# dmpac_targetdb register map
Vendor: Texas Instruments
Registers are 32-bit, read-write, no defined reset value unless marked. A register's access mark holds for its fields unless they carry their own. Offsets are as the file gives them; [hi:lo] are bit positions; {n}, {i} and the like mark numbered series; 'fields as' and 'values as' point back to an identical list.

## DMPAC (part 2 of 5) — Depth and Motion Perception Accelerator (DMPAC)
0x44 exception_pend_clear — The Exception Logging Pending Clear Register allows to clear the pend signal.
  [1:0] pend_clr — Write a 1 to clear the exception pend signal.
0x44 exception_pend_clear — The Exception Logging Pending Clear Register allows to clear the pend signal.
  [1:0] pend_clr — Write a 1 to clear the exception pend signal.
{0x44+0x400*i} msram{i}_fw_region_2_permission_0 (i=0..3) — The FW Region 2 Permission 0 Register defines the permissions for the slave ksbus_msram{i}.slv region 2 firewall.
  [16:8] priv_id — Allowed privid.
  [1] sec_supv_read — Secure supervisor read allowed.
  [2:1] sec_supv_cacheable — Secure supervisor cacheable allowed.
  [3:1] sec_supv_debug — Secure supervisor debug allowed.
  [4:1] sec_user_write — Secure user write allowed.
  [5:1] sec_user_read — Secure user read allowed.
  [6:1] sec_user_cacheable — Secure user cacheable allowed.
  [7:1] sec_user_debug — Secure user debug allowed.
  [8:1] nonsec_supv_write — Non-secure supervisor write allowed.
  [9:1] nonsec_supv_read — Non-secure supervisor read allowed.
  [10:1] nonsec_supv_cacheable — Non-secure supervisor cacheable allowed.
  [11:1] nonsec_supv_debug — Non-secure supervisor debug allowed.
  [12:1] nonsec_user_write — Non-secure user write allowed.
  [13:1] nonsec_user_read — Non-secure user read allowed.
  [14:1] nonsec_user_cacheable — Non-secure user cacheable allowed.
  [15:1] nonsec_user_debug — Non-secure user debug allowed.
  [1:0] sec_supv_write — Secure supervisor write allowed.
0x48 SETEVTENBL7 — System event detection enable register 7 (if number of events > 192)
  [1] Event194DetEn — Event(194) Detection Enable
  [n-193:1] Event{n}DetEn (n=195..224) — Event({n}) Detection Enable
  [1:0] Event193DetEn — Event(193) Detection Enable
0x48 bmbufbase access per field — Base address in SL2
  [24:3] depth_cfg rw — Depth of SL2 buffer
  [20:0] addr_cfg rw — SL2 base byte address. Should be aligned to 64 bytes
{0x48+0x400*i} msram{i}_fw_region_2_permission_1 (i=0..3) — The FW Region 2 Permission 1 Register defines the permissions for the slave ksbus_msram{i}.slv region 2 firewall.
  fields as msram0_fw_region_2_permission_0
0x4C SETEVTENBL8 — System event detection enable register 8 (if number of events > 224)
  [1] Event226DetEn — Event(226) Detection Enable
  [n-225:1] Event{n}DetEn (n=227..256) — Event({n}) Detection Enable
  [1:0] Event225DetEn — Event(225) Detection Enable
0x4C fvbufbase access per field — Base address in SL2
  fields as bmbufbase
{0x4C+0x400*i} msram{i}_fw_region_2_permission_2 (i=0..3) — The FW Region 2 Permission 2 Register defines the permissions for the slave ksbus_msram{i}.slv region 2 firewall.
  fields as msram0_fw_region_2_permission_0
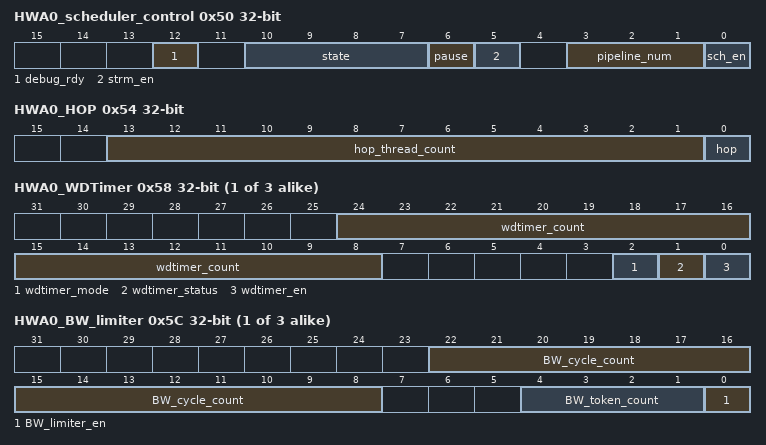
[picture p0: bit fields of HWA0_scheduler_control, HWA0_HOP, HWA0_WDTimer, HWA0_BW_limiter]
0x50 HWA0_scheduler_control access per field — Scheduler Control Register
  [12] debug_rdy rw — '0' -> HWA0 Scheduler resources must not be read during halted state. '1'-> HWA0 Scheduler resources are readable during halted state
  [10:7] state ro — Current state of HWA0 Scheduler
  [6] pause rw — '1' -> pause/suspend scheduler , '0' -> resume scheduler
  [5] strm_en rw — '1' -> Streaming input enable, '0' No streaming input
  [3:1] pipeline_num rw — Pipeline Number of HWA0 Scheduler
  [0] sch_en rw — scheduler enable; write '1' to enable scheduler
0x50 SETMSTID access per field — System Event Master ID
  [8:0] MASTID rw — HW Master ID for System Event module. Software may overwrite the value at any time, but this is only recommended for scenarios where top-level configuration errors result in a collision between HW master IDs
0x50 psa_ctrl access per field — Control register for calculating 32b CRC signature on stereo disparity output
  [1:0] psa_en_cfg rw — Enable calculating 32b CRC signature on 16b stereo disparity and confidence score output
{0x50+0x400*i} msram{i}_fw_region_2_start_address_l access per field (i=0..3) — The FW Region 2 Start Address Low Register defines the start address bits 31 to 0 for the slave ksbus_msram{i}.slv region 2 firewall.
  [20:12] start_address_l rw — Start address bits 31 to 12. Lowest 12 bits are forced to 0 as address must be 4KB aligned.
  [12:0] start_address_lsb ro — Start address bits 11 to 0 are forced to 0 as address must be 4KB aligned.
0x54 HWA0_HOP — Scheduler HOP Control Register. Help in detecting eop within scheduler. Once configured, it counts task/channel starts and stops issuing further start. Specifically useful for Head of pipe dma scheduler .
  [13:1] hop_thread_count — Number of Task count for Head of pipe
  [0] hop — '1' -> Head of Pipe producer Sch , '0' -> No hop
0x54 psa_signature ro — 32b CRC signature calculated on stereo disparity output
  [32:0] crc_sts — 32b CRC signature value as calculated on 16b stereo disparity and confidence score output
{0x54+0x400*i} msram{i}_fw_region_2_start_address_h (i=0..3) — The FW Region 2 Start Address High Register defines the start address bits 47 to 32 for the slave ksbus_msram{i}.slv region 2 firewall.
  [16:0] start_address_h — Start address bits 47 to 32.
{0x58+0xB4*i} HWA{i}_WDTimer access per field (i=0..2) — Watchdog timer control register
  [24:8] wdtimer_count ro — Current value of HWA{i} Scheduler watchdog timer count
  [2] wdtimer_mode rw — Watchdog timeout count '1' -> 128K , '0' -> 64K
  [1] wdtimer_status ro — HWA{i} Scheduler watchdog timer status '1' -> Timer Active '0' -> Timer Inactive (count is stable)
  [0] wdtimer_en rw — '1' -> activate watchdog timer for 64K VPAC/DMPAC cycles between task start and task done '0' -> Disable watchdog timer
{0x58+0x400*i} msram{i}_fw_region_2_end_address_l access per field (i=0..3) — The FW Region 2 End Address Low Register defines the end address bits 31 to 0 to include for the slave ksbus_msram{i}.slv region 2 firewall.
  [20:12] end_address_l rw — End address bits 31 to 12 to include in the match. Lowest 12 bits are forced to 1s as address must be 4KB aligned.
  [12:0] end_address_lsb ro — End address bits 11 to 0 are forced to 1s as address must be 4KB aligned minus 1.
{0x5C+0xB4*i} HWA{i}_BW_limiter (i=0..2) — Scheduler BW Control Register. Processing unit level BW control. Use DMA to eliminate peak system BW within processing units line/Block
  [22:8] BW_cycle_count — Average Cycle count between successive Task Start
  [4:1] BW_token_count — Max Token count to create average BW
  [0] BW_limiter_en — '1' -> Enable BW limiter function for HWA{i} sch, '0' --> Disable
{0x5C+0x400*i} msram{i}_fw_region_2_end_address_h (i=0..3) — The FW Region 2 End Address High Register defines the end address bits 47 to 32 to include for the slave ksbus_msram{i}.slv region 2 firewall.
  [16:0] end_address_h — End address bits 47 to 32 to include in the match.
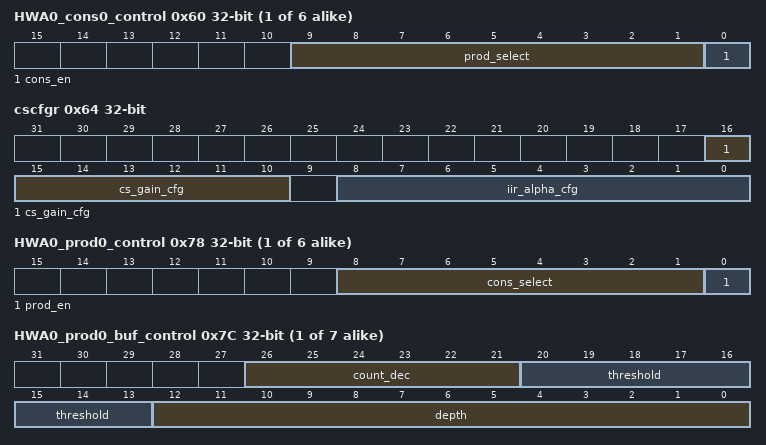
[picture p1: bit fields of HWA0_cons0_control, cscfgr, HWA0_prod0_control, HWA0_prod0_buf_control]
{0x60+4i} HWA0_cons{i}_control (i=0..5) — Controlling consumer socket {i} for HWA0
  [9:1] prod_select — producer select for HWA0 cons socket {i}
  [0] cons_en — '1' -> Consumer socket {i} enable , '0' Disable
0x60 msfr access per field — 5b unsigned integer for Step Search cost function
  [5:0] msf_cfg rw — Motion smoothness factor
0x60 HIST ro — SDE Histogram registers stores the counter value of how many confidence scores (scaled to 7-bits) have fallen into each bin
  [21:11] rsvd — Always read as 0. Writes have no effect.
  [21:0] bin_sts — BIN accumulated counter value. Clear to 0 within a 128 cycle window after hts_sde_init is asserted.
{0x60+0x400*i} msram{i}_fw_region_3_control (i=0..3) — The FW Region 3 Control Register defines the control fields for the slave ksbus_msram{i}.slv region 3 firewall.
  [4:1] lock — Lock region. Once set region values cannot be modified.
  [8:1] background — Background enable for region. There can be 1 backgroun region per FW and foreground regions can have overlapping addresses only with the background region.
  [9:1] cache_mode — Cache mode for region. Set to 1 to check cache permissions. Set to 0 to ignore cache permissions.
  [4:0] enable — Enable region. A value of 0xA enables, others disable.
0x64 cscfgr access per field — Feature filter parameters, confidence score scaling factor setup
  [16:10] cs_gain_cfg rw — Multiplier factor (Gain) for the combined confidence score. The sum of individual scores from different decision trees are multiplied by CS Gain before scaling to final 4bit (16 levels) confidence score value.
  [8:0] iir_alpha_cfg rw — Coefficient for IIR filter used for smoothing horizontal flow vector gradient. The usage can be illustrated as:SmoothU(i,j)= [ U(i,j)*alpha + SmoothU(i-1,j)*beta + round ]>>8where beta = 256-alpharound = 128
{0x64+0x400*i} msram{i}_fw_region_3_permission_0 (i=0..3) — The FW Region 3 Permission 0 Register defines the permissions for the slave ksbus_msram{i}.slv region 3 firewall.
  fields as msram0_fw_region_2_permission_0
{0x68+0x400*i} msram{i}_fw_region_3_permission_1 (i=0..3) — The FW Region 3 Permission 1 Register defines the permissions for the slave ksbus_msram{i}.slv region 3 firewall.
  fields as msram0_fw_region_2_permission_0
{0x6C+0x400*i} msram{i}_fw_region_3_permission_2 (i=0..3) — The FW Region 3 Permission 2 Register defines the permissions for the slave ksbus_msram{i}.slv region 3 firewall.
  fields as msram0_fw_region_2_permission_0
0x70 psa_ctrl access per field — Control register for calculating 32b CRC signature on flow vector output
  [1:0] psa_en_cfg rw — Enable calculating 32b CRC signature on 32b flow vector and confidence score output
{0x70+0x400*i} msram{i}_fw_region_3_start_address_l access per field (i=0..3) — The FW Region 3 Start Address Low Register defines the start address bits 31 to 0 for the slave ksbus_msram{i}.slv region 3 firewall.
  fields as msram0_fw_region_2_start_address_l
0x74 psa_signature ro — 32b CRC signature calculated on flow vector output
  [32:0] crc_sts — 32b CRC signature value as calculated on 32b flow vector and confidence score output
{0x74+0x400*i} msram{i}_fw_region_3_start_address_h (i=0..3) — The FW Region 3 Start Address High Register defines the start address bits 47 to 32 for the slave ksbus_msram{i}.slv region 3 firewall.
  [16:0] start_address_h — Start address bits 47 to 32.
{0x78+0x14*i} HWA0_prod{i}_control (i=0..5) — Controlling producer socket{i} for HWA0
  [8:1] cons_select — consumer select for HWA0 prod socket {i}. Used in decrementing count of producer buffer
  [0] prod_en — '1' -> Producer socket 0 enable , '0' Disable
{0x78+0x400*i} msram{i}_fw_region_3_end_address_l access per field (i=0..3) — The FW Region 3 End Address Low Register defines the end address bits 31 to 0 to include for the slave ksbus_msram{i}.slv region 3 firewall.
  fields as msram0_fw_region_2_end_address_l
{0x7C+0x14*i} HWA0_prod{i}_buf_control (i=0..6) — Controlling producer socket{i} buffer for HWA0
  [26:21] count_dec — Count decrement value for prod count
  [20:13] threshold — Count threshold to generate pend for consumer
  [12:0] depth — Maximum number of producer buffer count
{0x7C+0x400*i} msram{i}_fw_region_3_end_address_h (i=0..3) — The FW Region 3 End Address High Register defines the end address bits 47 to 32 to include for the slave ksbus_msram{i}.slv region 3 firewall.
  fields as msram0_fw_region_2_end_address_h
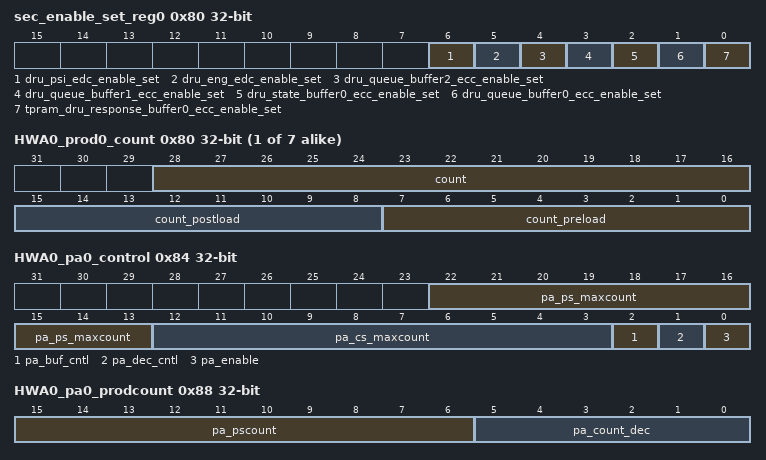
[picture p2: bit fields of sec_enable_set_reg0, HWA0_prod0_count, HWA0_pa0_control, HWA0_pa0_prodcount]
0x80 sec_enable_set_reg0 — Interrupt Enable Set Register 0
  [6] dru_psi_edc_enable_set — Interrupt Enable Set Register for dru_psi_edc_pend
  [5] dru_eng_edc_enable_set — Interrupt Enable Set Register for dru_eng_edc_pend
  [4] dru_queue_buffer2_ecc_enable_set — Interrupt Enable Set Register for dru_queue_buffer2_ecc_pend
  [3] dru_queue_buffer1_ecc_enable_set — Interrupt Enable Set Register for dru_queue_buffer1_ecc_pend
  [2] dru_state_buffer0_ecc_enable_set — Interrupt Enable Set Register for dru_state_buffer0_ecc_pend
  [1] dru_queue_buffer0_ecc_enable_set — Interrupt Enable Set Register for dru_queue_buffer0_ecc_pend
  [0] tpram_dru_response_buffer0_ecc_enable_set — Interrupt Enable Set Register for tpram_dru_response_buffer0_ecc_pend
{0x80+0x14*i} HWA0_prod{i}_count access per field (i=0..6) — Defining count values for pre/post load for generating pend by HWA0 prod{i}
  [28:16] count ro — current count value
  [15:8] count_postload rw — count postload after producer max thread count reached
  [7:0] count_preload rw — count preload after scheduler start/init
0x80 dru_err_evt_set0 wo — DRU Error Event Set Register
  [1] err_evt1 — Set the Error Event for channel 1
  [n:1] err_evt{n} (n=2..31) — Set the Error Event for channel {n}
  [1:0] err_evt0 — Set the Error Event for channel 0
0x84 HWA0_pa0_control — control register to manage pattern adapter on HWA0 prod socket0
  [22:13] pa_ps_maxcount — destination count for pattern adaptation (N), M --> N
  [12:3] pa_cs_maxcount — source count for pattern adaptation (M), M --> N
  [2] pa_buf_cntl — '1' -> Apply threshold, count_preload and count_postload on pattern adapter count (use this only when pa_enable='1') '0' -> Apply threshold, count_preload and count_postload on prod count (same behavior as if no pattern adapter. Note when pa_enable='1' and pa_buf_cntl='0' threshold is not used and ignored)
  [1] pa_dec_cntl — '1' -> post pattern adaptation, decrement ps count by count_dec , '0' -> post pattern adaptation, decrement ps count by pa_cs_maxcount
  [0] pa_enable — '1' -> pa enable, '0' -> disable
0x88 HWA0_pa0_prodcount access per field — count values for HWA0 prod socket0
  [15:6] pa_pscount ro — current count value of pa prod count
  [5:0] pa_count_dec rw — Decrement count value of pa_prod_count after pattern adapter prod count reaches threshold
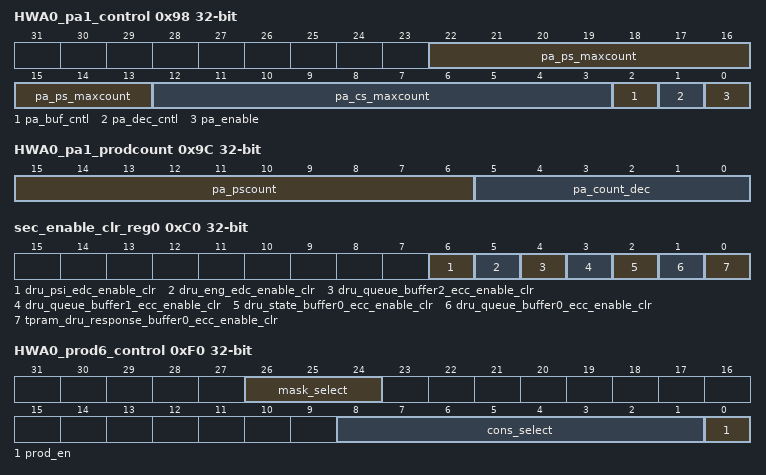
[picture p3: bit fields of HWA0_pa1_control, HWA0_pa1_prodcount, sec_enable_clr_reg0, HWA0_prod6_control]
0x98 HWA0_pa1_control — control register to manage pattern adapter on HWA0 prod socket1
  fields as HWA0_pa0_control
0x9C HWA0_pa1_prodcount access per field — count values for HWA0 prod socket1
  fields as HWA0_pa0_prodcount
0xC0 sec_enable_clr_reg0 — Interrupt Enable Clear Register 0
  [6] dru_psi_edc_enable_clr — Interrupt Enable Clear Register for dru_psi_edc_pend
  [5] dru_eng_edc_enable_clr — Interrupt Enable Clear Register for dru_eng_edc_pend
  [4] dru_queue_buffer2_ecc_enable_clr — Interrupt Enable Clear Register for dru_queue_buffer2_ecc_pend
  [3] dru_queue_buffer1_ecc_enable_clr — Interrupt Enable Clear Register for dru_queue_buffer1_ecc_pend
  [2] dru_state_buffer0_ecc_enable_clr — Interrupt Enable Clear Register for dru_state_buffer0_ecc_pend
  [1] dru_queue_buffer0_ecc_enable_clr — Interrupt Enable Clear Register for dru_queue_buffer0_ecc_pend
  [0] tpram_dru_response_buffer0_ecc_enable_clr — Interrupt Enable Clear Register for tpram_dru_response_buffer0_ecc_pend
0xC0 dru_local_evt_set0 wo — DRU Local Event Set Register
  [1] comp_evt1 — Set the Local Event for channel 1
  [n:1] comp_evt{n} (n=2..31) — Set the Local Event for channel {n}
  [1:0] comp_evt0 — Set the Local Event for channel 0
0xF0 HWA0_prod6_control — Controlling producer socket6 for HWA0
  [26:24] mask_select — define which tdone_mask apply to prod socket 6. tdone_mask[mask_select] applies to prod_socket6
  [8:1] cons_select — consumer select for HWA0 prod socket 6. Used in decrementing count of producer buffer
  [0] prod_en — '1' -> Producer socket 0 enable , '0' Disable
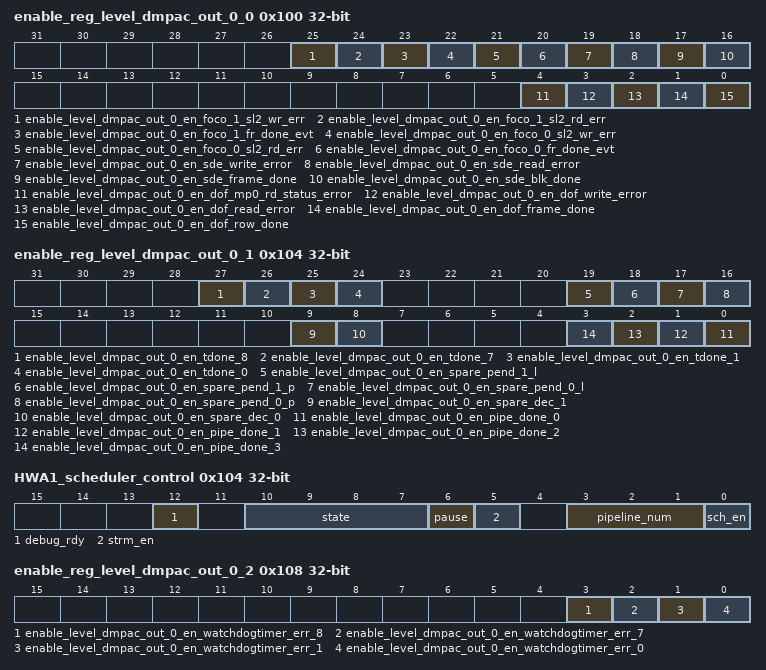
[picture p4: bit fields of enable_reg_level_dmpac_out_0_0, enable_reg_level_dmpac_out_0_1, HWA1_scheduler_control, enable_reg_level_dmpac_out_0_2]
0x100 enable_reg_level_dmpac_out_0_0 — Enable Register 0
  [25] enable_level_dmpac_out_0_en_foco_1_sl2_wr_err — Enable Set for level_dmpac_out_0_en_foco_1_sl2_wr_err
  [24] enable_level_dmpac_out_0_en_foco_1_sl2_rd_err — Enable Set for level_dmpac_out_0_en_foco_1_sl2_rd_err
  [23] enable_level_dmpac_out_0_en_foco_1_fr_done_evt — Enable Set for level_dmpac_out_0_en_foco_1_fr_done_evt
  [22] enable_level_dmpac_out_0_en_foco_0_sl2_wr_err — Enable Set for level_dmpac_out_0_en_foco_0_sl2_wr_err
  [21] enable_level_dmpac_out_0_en_foco_0_sl2_rd_err — Enable Set for level_dmpac_out_0_en_foco_0_sl2_rd_err
  [20] enable_level_dmpac_out_0_en_foco_0_fr_done_evt — Enable Set for level_dmpac_out_0_en_foco_0_fr_done_evt
  [19] enable_level_dmpac_out_0_en_sde_write_error — Enable Set for level_dmpac_out_0_en_sde_write_error
  [18] enable_level_dmpac_out_0_en_sde_read_error — Enable Set for level_dmpac_out_0_en_sde_read_error
  [17] enable_level_dmpac_out_0_en_sde_frame_done — Enable Set for level_dmpac_out_0_en_sde_frame_done
  [16] enable_level_dmpac_out_0_en_sde_blk_done — Enable Set for level_dmpac_out_0_en_sde_blk_done
  [4] enable_level_dmpac_out_0_en_dof_mp0_rd_status_error — Enable Set for level_dmpac_out_0_en_dof_mp0_rd_status_error
  [3] enable_level_dmpac_out_0_en_dof_write_error — Enable Set for level_dmpac_out_0_en_dof_write_error
  [2] enable_level_dmpac_out_0_en_dof_read_error — Enable Set for level_dmpac_out_0_en_dof_read_error
  [1] enable_level_dmpac_out_0_en_dof_frame_done — Enable Set for level_dmpac_out_0_en_dof_frame_done
  [0] enable_level_dmpac_out_0_en_dof_row_done — Enable Set for level_dmpac_out_0_en_dof_row_done
0x104 enable_reg_level_dmpac_out_0_1 — Enable Register 1
  [27] enable_level_dmpac_out_0_en_tdone_8 — Enable Set for level_dmpac_out_0_en_tdone_8
  [26] enable_level_dmpac_out_0_en_tdone_7 — Enable Set for level_dmpac_out_0_en_tdone_7
  [25] enable_level_dmpac_out_0_en_tdone_1 — Enable Set for level_dmpac_out_0_en_tdone_1
  [24] enable_level_dmpac_out_0_en_tdone_0 — Enable Set for level_dmpac_out_0_en_tdone_0
  [19] enable_level_dmpac_out_0_en_spare_pend_1_l — Enable Set for level_dmpac_out_0_en_spare_pend_1_l
  [18] enable_level_dmpac_out_0_en_spare_pend_1_p — Enable Set for level_dmpac_out_0_en_spare_pend_1_p
  [17] enable_level_dmpac_out_0_en_spare_pend_0_l — Enable Set for level_dmpac_out_0_en_spare_pend_0_l
  [16] enable_level_dmpac_out_0_en_spare_pend_0_p — Enable Set for level_dmpac_out_0_en_spare_pend_0_p
  [9] enable_level_dmpac_out_0_en_spare_dec_1 — Enable Set for level_dmpac_out_0_en_spare_dec_1
  [8] enable_level_dmpac_out_0_en_spare_dec_0 — Enable Set for level_dmpac_out_0_en_spare_dec_0
  [n] enable_level_dmpac_out_0_en_pipe_done_{n} (n=0..3) — Enable Set for level_dmpac_out_0_en_pipe_done_{n}
0x104 HWA1_scheduler_control access per field — Scheduler Control Register
  [12] debug_rdy rw — '0' -> HWA1 Scheduler resources must not be read during halted state. '1'-> HWA1 Scheduler resources are readable during halted state
  [10:7] state ro — Current state of HWA1 Scheduler
  [6] pause rw — '1' -> pause/suspend scheduler , '0' -> resume scheduler
  [5] strm_en rw — '1' -> Streaming input enable, '0' No streaming input
  [3:1] pipeline_num rw — Pipeline Number of HWA1 Scheduler
  [0] sch_en rw — scheduler enable; write '1' to enable scheduler
0x108 enable_reg_level_dmpac_out_0_2 — Enable Register 2
  [3] enable_level_dmpac_out_0_en_watchdogtimer_err_8 — Enable Set for level_dmpac_out_0_en_watchdogtimer_err_8
  [2] enable_level_dmpac_out_0_en_watchdogtimer_err_7 — Enable Set for level_dmpac_out_0_en_watchdogtimer_err_7
  [1] enable_level_dmpac_out_0_en_watchdogtimer_err_1 — Enable Set for level_dmpac_out_0_en_watchdogtimer_err_1
  [0] enable_level_dmpac_out_0_en_watchdogtimer_err_0 — Enable Set for level_dmpac_out_0_en_watchdogtimer_err_0
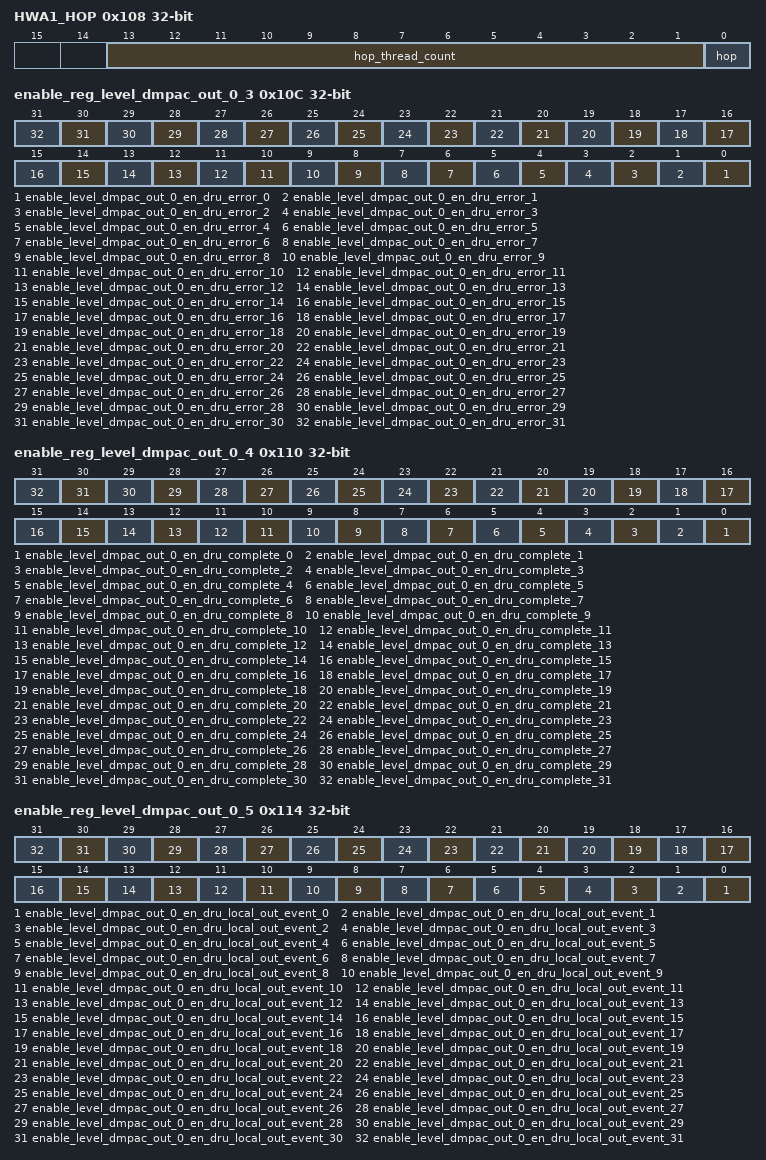
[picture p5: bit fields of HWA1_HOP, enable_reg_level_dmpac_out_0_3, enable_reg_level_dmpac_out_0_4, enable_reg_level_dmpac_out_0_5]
0x108 HWA1_HOP — Scheduler HOP Control Register. Help in detecting eop within scheduler. Once configured, it counts task/channel starts and stops issuing further start. Specifically useful for Head of pipe dma scheduler .
  fields as HWA0_HOP
0x10C enable_reg_level_dmpac_out_0_3 — Enable Register 3
  [n] enable_level_dmpac_out_0_en_dru_error_{n} (n=0..31) — Enable Set for level_dmpac_out_0_en_dru_error_{n}
0x110 enable_reg_level_dmpac_out_0_4 — Enable Register 4
  [n] enable_level_dmpac_out_0_en_dru_complete_{n} (n=0..31) — Enable Set for level_dmpac_out_0_en_dru_complete_{n}
0x114 enable_reg_level_dmpac_out_0_5 — Enable Register 5
  [n] enable_level_dmpac_out_0_en_dru_local_out_event_{n} (n=0..31) — Enable Set for level_dmpac_out_0_en_dru_local_out_event_{n}
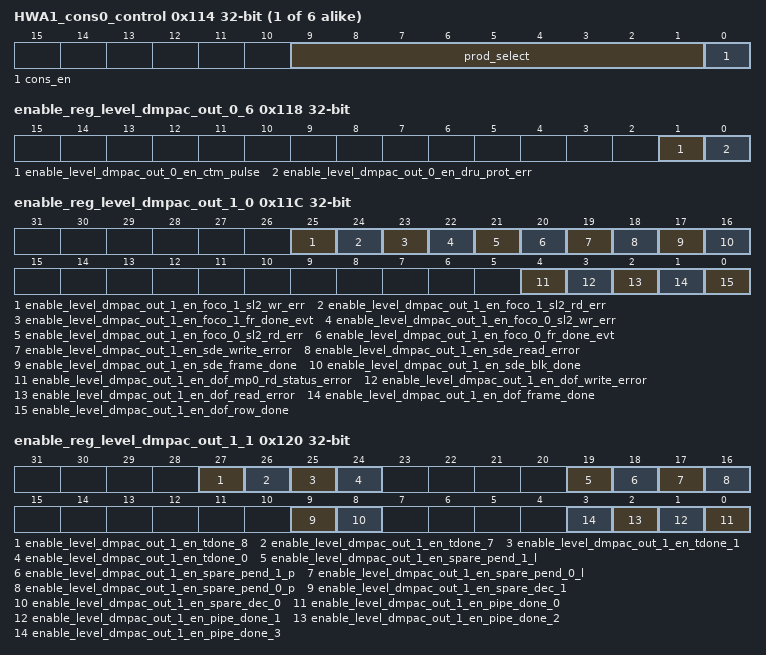
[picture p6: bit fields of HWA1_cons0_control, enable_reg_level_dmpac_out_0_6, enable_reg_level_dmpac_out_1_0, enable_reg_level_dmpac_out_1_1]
{0x114+4i} HWA1_cons{i}_control (i=0..5) — Controlling consumer socket {i} for HWA1
  [9:1] prod_select — producer select for HWA1 cons socket {i}
  [0] cons_en — '1' -> Consumer socket {i} enable , '0' Disable
0x118 enable_reg_level_dmpac_out_0_6 — Enable Register 6
  [1] enable_level_dmpac_out_0_en_ctm_pulse — Enable Set for level_dmpac_out_0_en_ctm_pulse
  [0] enable_level_dmpac_out_0_en_dru_prot_err — Enable Set for level_dmpac_out_0_en_dru_prot_err
0x11C enable_reg_level_dmpac_out_1_0 — Enable Register 7
  [25] enable_level_dmpac_out_1_en_foco_1_sl2_wr_err — Enable Set for level_dmpac_out_1_en_foco_1_sl2_wr_err
  [24] enable_level_dmpac_out_1_en_foco_1_sl2_rd_err — Enable Set for level_dmpac_out_1_en_foco_1_sl2_rd_err
  [23] enable_level_dmpac_out_1_en_foco_1_fr_done_evt — Enable Set for level_dmpac_out_1_en_foco_1_fr_done_evt
  [22] enable_level_dmpac_out_1_en_foco_0_sl2_wr_err — Enable Set for level_dmpac_out_1_en_foco_0_sl2_wr_err
  [21] enable_level_dmpac_out_1_en_foco_0_sl2_rd_err — Enable Set for level_dmpac_out_1_en_foco_0_sl2_rd_err
  [20] enable_level_dmpac_out_1_en_foco_0_fr_done_evt — Enable Set for level_dmpac_out_1_en_foco_0_fr_done_evt
  [19] enable_level_dmpac_out_1_en_sde_write_error — Enable Set for level_dmpac_out_1_en_sde_write_error
  [18] enable_level_dmpac_out_1_en_sde_read_error — Enable Set for level_dmpac_out_1_en_sde_read_error
  [17] enable_level_dmpac_out_1_en_sde_frame_done — Enable Set for level_dmpac_out_1_en_sde_frame_done
  [16] enable_level_dmpac_out_1_en_sde_blk_done — Enable Set for level_dmpac_out_1_en_sde_blk_done
  [4] enable_level_dmpac_out_1_en_dof_mp0_rd_status_error — Enable Set for level_dmpac_out_1_en_dof_mp0_rd_status_error
  [3] enable_level_dmpac_out_1_en_dof_write_error — Enable Set for level_dmpac_out_1_en_dof_write_error
  [2] enable_level_dmpac_out_1_en_dof_read_error — Enable Set for level_dmpac_out_1_en_dof_read_error
  [1] enable_level_dmpac_out_1_en_dof_frame_done — Enable Set for level_dmpac_out_1_en_dof_frame_done
  [0] enable_level_dmpac_out_1_en_dof_row_done — Enable Set for level_dmpac_out_1_en_dof_row_done
0x120 enable_reg_level_dmpac_out_1_1 — Enable Register 8
  [27] enable_level_dmpac_out_1_en_tdone_8 — Enable Set for level_dmpac_out_1_en_tdone_8
  [26] enable_level_dmpac_out_1_en_tdone_7 — Enable Set for level_dmpac_out_1_en_tdone_7
  [25] enable_level_dmpac_out_1_en_tdone_1 — Enable Set for level_dmpac_out_1_en_tdone_1
  [24] enable_level_dmpac_out_1_en_tdone_0 — Enable Set for level_dmpac_out_1_en_tdone_0
  [19] enable_level_dmpac_out_1_en_spare_pend_1_l — Enable Set for level_dmpac_out_1_en_spare_pend_1_l
  [18] enable_level_dmpac_out_1_en_spare_pend_1_p — Enable Set for level_dmpac_out_1_en_spare_pend_1_p
  [17] enable_level_dmpac_out_1_en_spare_pend_0_l — Enable Set for level_dmpac_out_1_en_spare_pend_0_l
  [16] enable_level_dmpac_out_1_en_spare_pend_0_p — Enable Set for level_dmpac_out_1_en_spare_pend_0_p
  [9] enable_level_dmpac_out_1_en_spare_dec_1 — Enable Set for level_dmpac_out_1_en_spare_dec_1
  [8] enable_level_dmpac_out_1_en_spare_dec_0 — Enable Set for level_dmpac_out_1_en_spare_dec_0
  [n] enable_level_dmpac_out_1_en_pipe_done_{n} (n=0..3) — Enable Set for level_dmpac_out_1_en_pipe_done_{n}
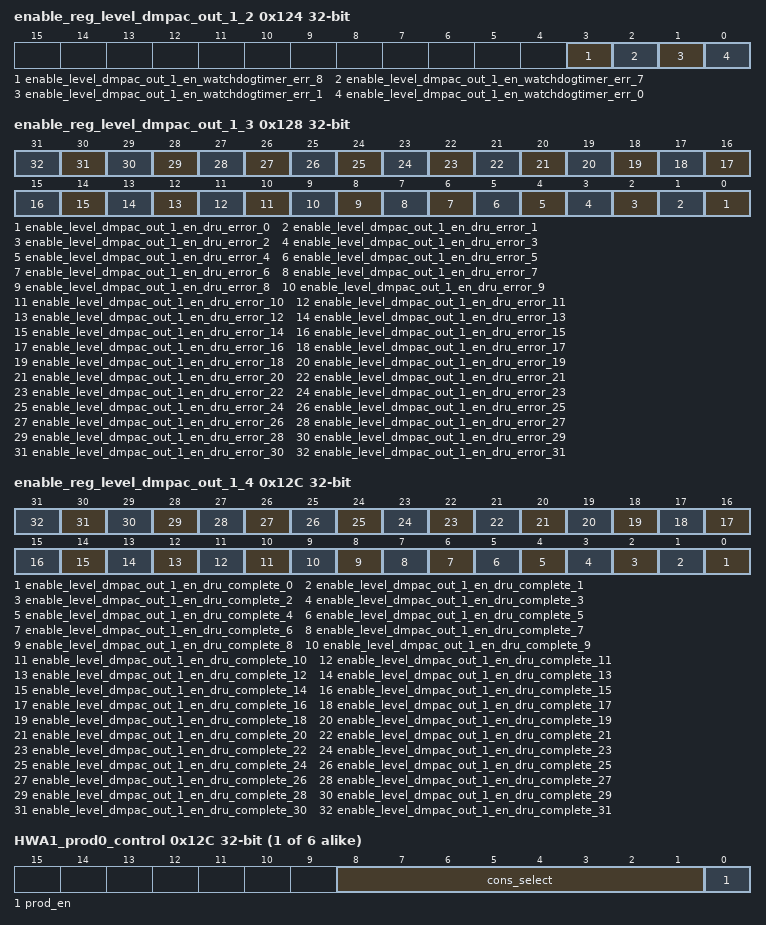
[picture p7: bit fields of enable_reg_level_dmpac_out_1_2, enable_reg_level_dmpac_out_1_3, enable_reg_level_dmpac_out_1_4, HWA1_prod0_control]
0x124 enable_reg_level_dmpac_out_1_2 — Enable Register 9
  [3] enable_level_dmpac_out_1_en_watchdogtimer_err_8 — Enable Set for level_dmpac_out_1_en_watchdogtimer_err_8
  [2] enable_level_dmpac_out_1_en_watchdogtimer_err_7 — Enable Set for level_dmpac_out_1_en_watchdogtimer_err_7
  [1] enable_level_dmpac_out_1_en_watchdogtimer_err_1 — Enable Set for level_dmpac_out_1_en_watchdogtimer_err_1
  [0] enable_level_dmpac_out_1_en_watchdogtimer_err_0 — Enable Set for level_dmpac_out_1_en_watchdogtimer_err_0
0x128 enable_reg_level_dmpac_out_1_3 — Enable Register 10
  [n] enable_level_dmpac_out_1_en_dru_error_{n} (n=0..31) — Enable Set for level_dmpac_out_1_en_dru_error_{n}
0x12C enable_reg_level_dmpac_out_1_4 — Enable Register 11
  [n] enable_level_dmpac_out_1_en_dru_complete_{n} (n=0..31) — Enable Set for level_dmpac_out_1_en_dru_complete_{n}
{0x12C+0x14*i} HWA1_prod{i}_control (i=0..5) — Controlling producer socket{i} for HWA1
  [8:1] cons_select — consumer select for HWA1 prod socket {i}. Used in decrementing count of producer buffer
  [0] prod_en — '1' -> Producer socket 0 enable , '0' Disable
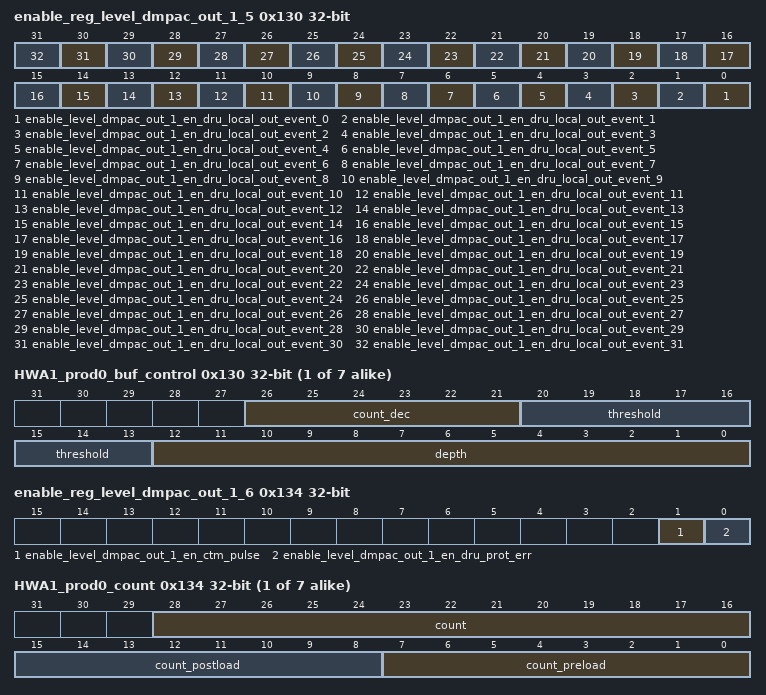
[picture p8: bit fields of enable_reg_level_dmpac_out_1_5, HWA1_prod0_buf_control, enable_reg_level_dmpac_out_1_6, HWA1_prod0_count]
0x130 enable_reg_level_dmpac_out_1_5 — Enable Register 12
  [n] enable_level_dmpac_out_1_en_dru_local_out_event_{n} (n=0..31) — Enable Set for level_dmpac_out_1_en_dru_local_out_event_{n}
{0x130+0x14*i} HWA1_prod{i}_buf_control (i=0..6) — Controlling producer socket{i} buffer for HWA1
  fields as HWA0_prod0_buf_control
0x134 enable_reg_level_dmpac_out_1_6 — Enable Register 13
  [1] enable_level_dmpac_out_1_en_ctm_pulse — Enable Set for level_dmpac_out_1_en_ctm_pulse
  [0] enable_level_dmpac_out_1_en_dru_prot_err — Enable Set for level_dmpac_out_1_en_dru_prot_err
{0x134+0x14*i} HWA1_prod{i}_count access per field (i=0..6) — Defining count values for pre/post load for generating pend by HWA1 prod{i}
  fields as HWA0_prod0_count
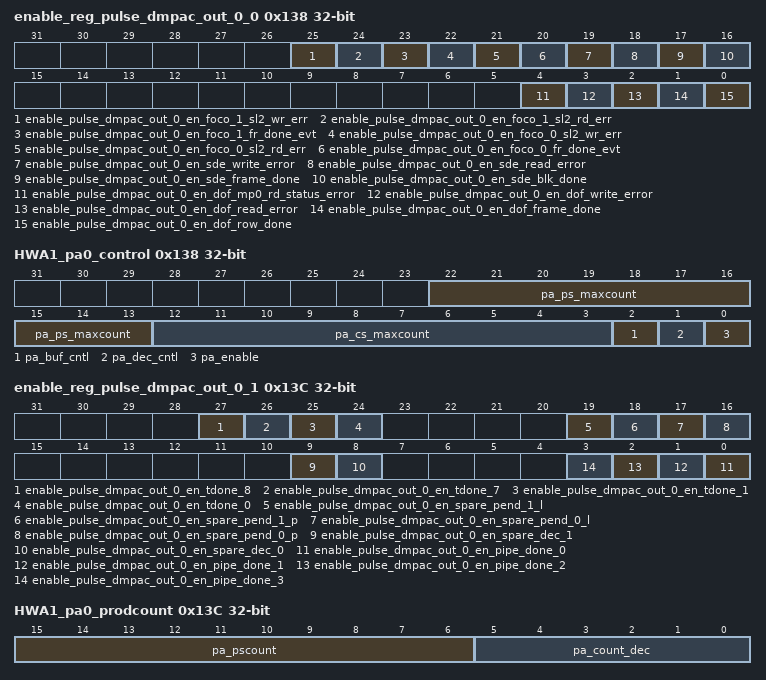
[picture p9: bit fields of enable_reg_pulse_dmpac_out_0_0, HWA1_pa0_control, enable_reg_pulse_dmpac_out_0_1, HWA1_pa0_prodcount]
0x138 enable_reg_pulse_dmpac_out_0_0 — Enable Register 14
  [25] enable_pulse_dmpac_out_0_en_foco_1_sl2_wr_err — Enable Set for pulse_dmpac_out_0_en_foco_1_sl2_wr_err
  [24] enable_pulse_dmpac_out_0_en_foco_1_sl2_rd_err — Enable Set for pulse_dmpac_out_0_en_foco_1_sl2_rd_err
  [23] enable_pulse_dmpac_out_0_en_foco_1_fr_done_evt — Enable Set for pulse_dmpac_out_0_en_foco_1_fr_done_evt
  [22] enable_pulse_dmpac_out_0_en_foco_0_sl2_wr_err — Enable Set for pulse_dmpac_out_0_en_foco_0_sl2_wr_err
  [21] enable_pulse_dmpac_out_0_en_foco_0_sl2_rd_err — Enable Set for pulse_dmpac_out_0_en_foco_0_sl2_rd_err
  [20] enable_pulse_dmpac_out_0_en_foco_0_fr_done_evt — Enable Set for pulse_dmpac_out_0_en_foco_0_fr_done_evt
  [19] enable_pulse_dmpac_out_0_en_sde_write_error — Enable Set for pulse_dmpac_out_0_en_sde_write_error
  [18] enable_pulse_dmpac_out_0_en_sde_read_error — Enable Set for pulse_dmpac_out_0_en_sde_read_error
  [17] enable_pulse_dmpac_out_0_en_sde_frame_done — Enable Set for pulse_dmpac_out_0_en_sde_frame_done
  [16] enable_pulse_dmpac_out_0_en_sde_blk_done — Enable Set for pulse_dmpac_out_0_en_sde_blk_done
  [4] enable_pulse_dmpac_out_0_en_dof_mp0_rd_status_error — Enable Set for pulse_dmpac_out_0_en_dof_mp0_rd_status_error
  [3] enable_pulse_dmpac_out_0_en_dof_write_error — Enable Set for pulse_dmpac_out_0_en_dof_write_error
  [2] enable_pulse_dmpac_out_0_en_dof_read_error — Enable Set for pulse_dmpac_out_0_en_dof_read_error
  [1] enable_pulse_dmpac_out_0_en_dof_frame_done — Enable Set for pulse_dmpac_out_0_en_dof_frame_done
  [0] enable_pulse_dmpac_out_0_en_dof_row_done — Enable Set for pulse_dmpac_out_0_en_dof_row_done
0x138 HWA1_pa0_control — control register to manage pattern adapter on HWA1 prod socket0
  fields as HWA0_pa0_control
0x13C ded_eoi_reg — EOI Register
  [0] eoi_wr
0x13C enable_reg_pulse_dmpac_out_0_1 — Enable Register 15
  [27] enable_pulse_dmpac_out_0_en_tdone_8 — Enable Set for pulse_dmpac_out_0_en_tdone_8
  [26] enable_pulse_dmpac_out_0_en_tdone_7 — Enable Set for pulse_dmpac_out_0_en_tdone_7
  [25] enable_pulse_dmpac_out_0_en_tdone_1 — Enable Set for pulse_dmpac_out_0_en_tdone_1
  [24] enable_pulse_dmpac_out_0_en_tdone_0 — Enable Set for pulse_dmpac_out_0_en_tdone_0
  [19] enable_pulse_dmpac_out_0_en_spare_pend_1_l — Enable Set for pulse_dmpac_out_0_en_spare_pend_1_l
  [18] enable_pulse_dmpac_out_0_en_spare_pend_1_p — Enable Set for pulse_dmpac_out_0_en_spare_pend_1_p
  [17] enable_pulse_dmpac_out_0_en_spare_pend_0_l — Enable Set for pulse_dmpac_out_0_en_spare_pend_0_l
  [16] enable_pulse_dmpac_out_0_en_spare_pend_0_p — Enable Set for pulse_dmpac_out_0_en_spare_pend_0_p
  [9] enable_pulse_dmpac_out_0_en_spare_dec_1 — Enable Set for pulse_dmpac_out_0_en_spare_dec_1
  [8] enable_pulse_dmpac_out_0_en_spare_dec_0 — Enable Set for pulse_dmpac_out_0_en_spare_dec_0
  [n] enable_pulse_dmpac_out_0_en_pipe_done_{n} (n=0..3) — Enable Set for pulse_dmpac_out_0_en_pipe_done_{n}
0x13C HWA1_pa0_prodcount access per field — count values for HWA1 prod socket0
  fields as HWA0_pa0_prodcount
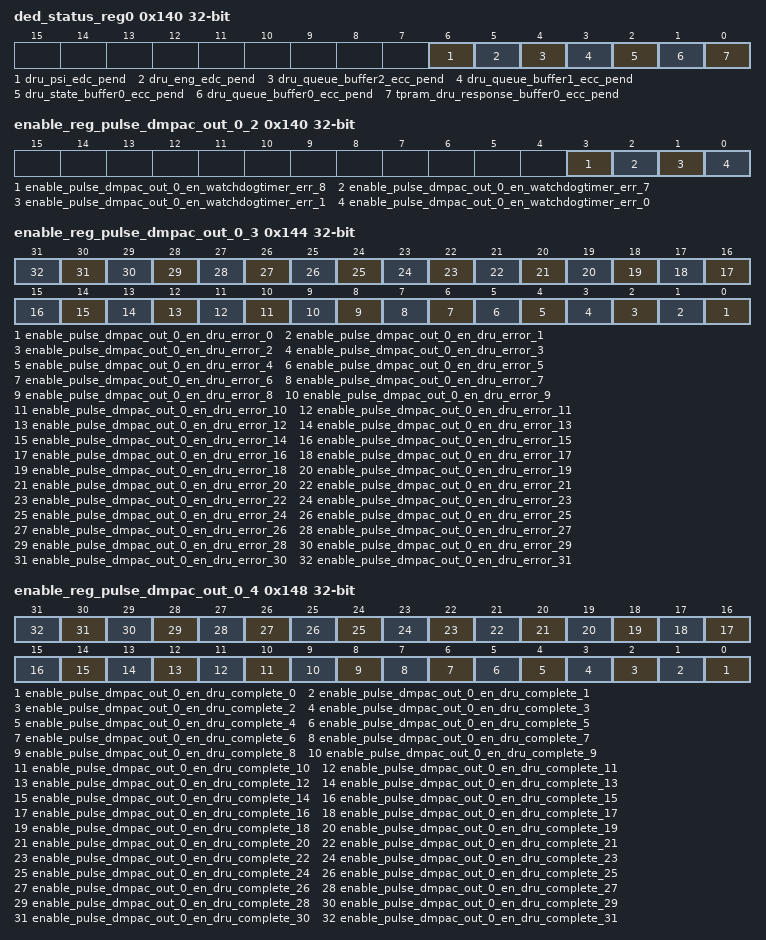
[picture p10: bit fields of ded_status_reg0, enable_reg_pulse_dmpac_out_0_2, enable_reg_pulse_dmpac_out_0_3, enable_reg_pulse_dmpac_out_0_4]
0x140 ded_status_reg0 — Interrupt Status Register 0
  [6] dru_psi_edc_pend — Interrupt Pending Status for dru_psi_edc_pend
  [5] dru_eng_edc_pend — Interrupt Pending Status for dru_eng_edc_pend
  [4] dru_queue_buffer2_ecc_pend — Interrupt Pending Status for dru_queue_buffer2_ecc_pend
  [3] dru_queue_buffer1_ecc_pend — Interrupt Pending Status for dru_queue_buffer1_ecc_pend
  [2] dru_state_buffer0_ecc_pend — Interrupt Pending Status for dru_state_buffer0_ecc_pend
  [1] dru_queue_buffer0_ecc_pend — Interrupt Pending Status for dru_queue_buffer0_ecc_pend
  [0] tpram_dru_response_buffer0_ecc_pend — Interrupt Pending Status for tpram_dru_response_buffer0_ecc_pend
0x140 enable_reg_pulse_dmpac_out_0_2 — Enable Register 16
  [3] enable_pulse_dmpac_out_0_en_watchdogtimer_err_8 — Enable Set for pulse_dmpac_out_0_en_watchdogtimer_err_8
  [2] enable_pulse_dmpac_out_0_en_watchdogtimer_err_7 — Enable Set for pulse_dmpac_out_0_en_watchdogtimer_err_7
  [1] enable_pulse_dmpac_out_0_en_watchdogtimer_err_1 — Enable Set for pulse_dmpac_out_0_en_watchdogtimer_err_1
  [0] enable_pulse_dmpac_out_0_en_watchdogtimer_err_0 — Enable Set for pulse_dmpac_out_0_en_watchdogtimer_err_0
0x140 psa_signature ro — The PSA_SIGNATURE register returns the captured PSA signature value of the last frame data of output channel [a].
  [32:0] value — 32-bit CRC signature value
0x140 psa_signature ro — The PSA_SIGNATURE register returns the captured PSA signature value of the last frame data of output channel [a].
  [32:0] value — 32-bit CRC signature value
0x144 enable_reg_pulse_dmpac_out_0_3 — Enable Register 17
  [n] enable_pulse_dmpac_out_0_en_dru_error_{n} (n=0..31) — Enable Set for pulse_dmpac_out_0_en_dru_error_{n}
0x148 enable_reg_pulse_dmpac_out_0_4 — Enable Register 18
  [n] enable_pulse_dmpac_out_0_en_dru_complete_{n} (n=0..31) — Enable Set for pulse_dmpac_out_0_en_dru_complete_{n}
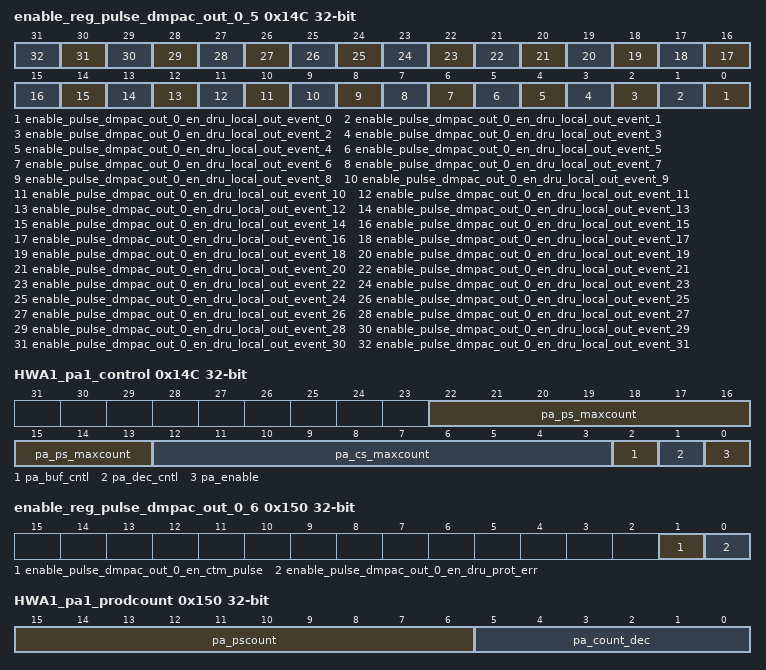
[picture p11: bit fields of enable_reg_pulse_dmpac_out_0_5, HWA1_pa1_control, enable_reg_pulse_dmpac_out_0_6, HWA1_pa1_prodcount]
0x14C enable_reg_pulse_dmpac_out_0_5 — Enable Register 19
  [n] enable_pulse_dmpac_out_0_en_dru_local_out_event_{n} (n=0..31) — Enable Set for pulse_dmpac_out_0_en_dru_local_out_event_{n}
0x14C HWA1_pa1_control — control register to manage pattern adapter on HWA1 prod socket1
  fields as HWA0_pa0_control
0x150 enable_reg_pulse_dmpac_out_0_6 — Enable Register 20
  [1] enable_pulse_dmpac_out_0_en_ctm_pulse — Enable Set for pulse_dmpac_out_0_en_ctm_pulse
  [0] enable_pulse_dmpac_out_0_en_dru_prot_err — Enable Set for pulse_dmpac_out_0_en_dru_prot_err
0x150 HWA1_pa1_prodcount access per field — count values for HWA1 prod socket1
  fields as HWA0_pa0_prodcount
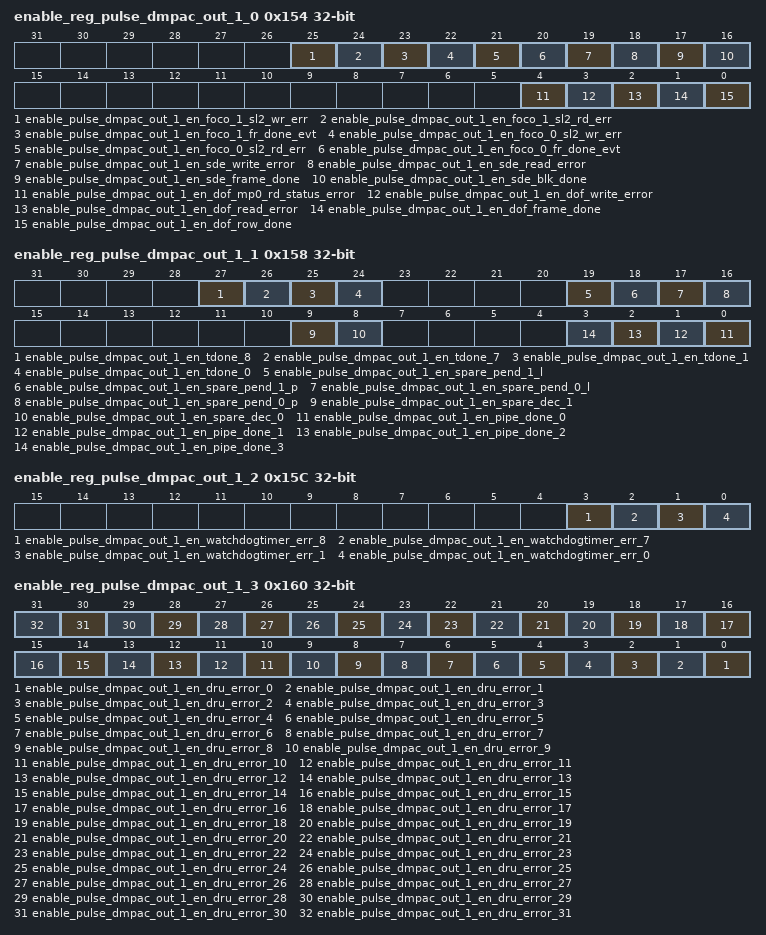
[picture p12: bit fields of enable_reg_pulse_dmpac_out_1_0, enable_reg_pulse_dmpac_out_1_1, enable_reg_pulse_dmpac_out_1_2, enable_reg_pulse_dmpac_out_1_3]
0x154 enable_reg_pulse_dmpac_out_1_0 — Enable Register 21
  [25] enable_pulse_dmpac_out_1_en_foco_1_sl2_wr_err — Enable Set for pulse_dmpac_out_1_en_foco_1_sl2_wr_err
  [24] enable_pulse_dmpac_out_1_en_foco_1_sl2_rd_err — Enable Set for pulse_dmpac_out_1_en_foco_1_sl2_rd_err
  [23] enable_pulse_dmpac_out_1_en_foco_1_fr_done_evt — Enable Set for pulse_dmpac_out_1_en_foco_1_fr_done_evt
  [22] enable_pulse_dmpac_out_1_en_foco_0_sl2_wr_err — Enable Set for pulse_dmpac_out_1_en_foco_0_sl2_wr_err
  [21] enable_pulse_dmpac_out_1_en_foco_0_sl2_rd_err — Enable Set for pulse_dmpac_out_1_en_foco_0_sl2_rd_err
  [20] enable_pulse_dmpac_out_1_en_foco_0_fr_done_evt — Enable Set for pulse_dmpac_out_1_en_foco_0_fr_done_evt
  [19] enable_pulse_dmpac_out_1_en_sde_write_error — Enable Set for pulse_dmpac_out_1_en_sde_write_error
  [18] enable_pulse_dmpac_out_1_en_sde_read_error — Enable Set for pulse_dmpac_out_1_en_sde_read_error
  [17] enable_pulse_dmpac_out_1_en_sde_frame_done — Enable Set for pulse_dmpac_out_1_en_sde_frame_done
  [16] enable_pulse_dmpac_out_1_en_sde_blk_done — Enable Set for pulse_dmpac_out_1_en_sde_blk_done
  [4] enable_pulse_dmpac_out_1_en_dof_mp0_rd_status_error — Enable Set for pulse_dmpac_out_1_en_dof_mp0_rd_status_error
  [3] enable_pulse_dmpac_out_1_en_dof_write_error — Enable Set for pulse_dmpac_out_1_en_dof_write_error
  [2] enable_pulse_dmpac_out_1_en_dof_read_error — Enable Set for pulse_dmpac_out_1_en_dof_read_error
  [1] enable_pulse_dmpac_out_1_en_dof_frame_done — Enable Set for pulse_dmpac_out_1_en_dof_frame_done
  [0] enable_pulse_dmpac_out_1_en_dof_row_done — Enable Set for pulse_dmpac_out_1_en_dof_row_done
0x158 enable_reg_pulse_dmpac_out_1_1 — Enable Register 22
  [27] enable_pulse_dmpac_out_1_en_tdone_8 — Enable Set for pulse_dmpac_out_1_en_tdone_8
  [26] enable_pulse_dmpac_out_1_en_tdone_7 — Enable Set for pulse_dmpac_out_1_en_tdone_7
  [25] enable_pulse_dmpac_out_1_en_tdone_1 — Enable Set for pulse_dmpac_out_1_en_tdone_1
  [24] enable_pulse_dmpac_out_1_en_tdone_0 — Enable Set for pulse_dmpac_out_1_en_tdone_0
  [19] enable_pulse_dmpac_out_1_en_spare_pend_1_l — Enable Set for pulse_dmpac_out_1_en_spare_pend_1_l
  [18] enable_pulse_dmpac_out_1_en_spare_pend_1_p — Enable Set for pulse_dmpac_out_1_en_spare_pend_1_p
  [17] enable_pulse_dmpac_out_1_en_spare_pend_0_l — Enable Set for pulse_dmpac_out_1_en_spare_pend_0_l
  [16] enable_pulse_dmpac_out_1_en_spare_pend_0_p — Enable Set for pulse_dmpac_out_1_en_spare_pend_0_p
  [9] enable_pulse_dmpac_out_1_en_spare_dec_1 — Enable Set for pulse_dmpac_out_1_en_spare_dec_1
  [8] enable_pulse_dmpac_out_1_en_spare_dec_0 — Enable Set for pulse_dmpac_out_1_en_spare_dec_0
  [n] enable_pulse_dmpac_out_1_en_pipe_done_{n} (n=0..3) — Enable Set for pulse_dmpac_out_1_en_pipe_done_{n}
0x15C enable_reg_pulse_dmpac_out_1_2 — Enable Register 23
  [3] enable_pulse_dmpac_out_1_en_watchdogtimer_err_8 — Enable Set for pulse_dmpac_out_1_en_watchdogtimer_err_8
  [2] enable_pulse_dmpac_out_1_en_watchdogtimer_err_7 — Enable Set for pulse_dmpac_out_1_en_watchdogtimer_err_7
  [1] enable_pulse_dmpac_out_1_en_watchdogtimer_err_1 — Enable Set for pulse_dmpac_out_1_en_watchdogtimer_err_1
  [0] enable_pulse_dmpac_out_1_en_watchdogtimer_err_0 — Enable Set for pulse_dmpac_out_1_en_watchdogtimer_err_0
0x160 enable_reg_pulse_dmpac_out_1_3 — Enable Register 24
  [n] enable_pulse_dmpac_out_1_en_dru_error_{n} (n=0..31) — Enable Set for pulse_dmpac_out_1_en_dru_error_{n}
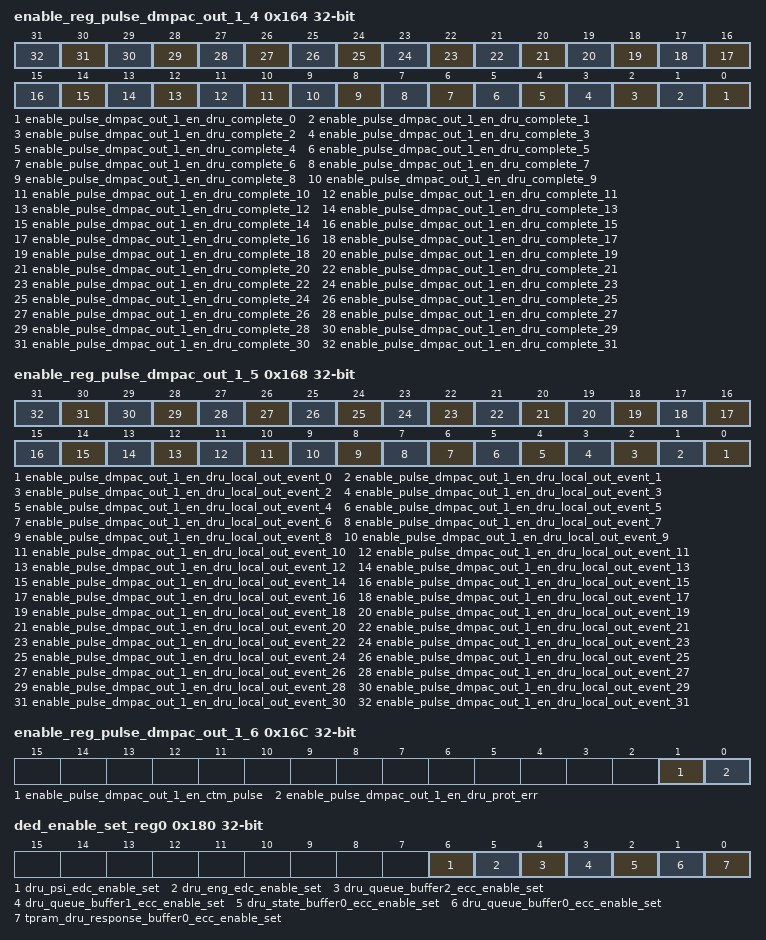
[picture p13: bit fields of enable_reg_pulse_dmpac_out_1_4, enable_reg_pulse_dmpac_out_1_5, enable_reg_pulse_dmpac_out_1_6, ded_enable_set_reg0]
0x164 enable_reg_pulse_dmpac_out_1_4 — Enable Register 25
  [n] enable_pulse_dmpac_out_1_en_dru_complete_{n} (n=0..31) — Enable Set for pulse_dmpac_out_1_en_dru_complete_{n}
0x168 enable_reg_pulse_dmpac_out_1_5 — Enable Register 26
  [n] enable_pulse_dmpac_out_1_en_dru_local_out_event_{n} (n=0..31) — Enable Set for pulse_dmpac_out_1_en_dru_local_out_event_{n}
0x16C enable_reg_pulse_dmpac_out_1_6 — Enable Register 27
  [1] enable_pulse_dmpac_out_1_en_ctm_pulse — Enable Set for pulse_dmpac_out_1_en_ctm_pulse
  [0] enable_pulse_dmpac_out_1_en_dru_prot_err — Enable Set for pulse_dmpac_out_1_en_dru_prot_err
0x180 ded_enable_set_reg0 — Interrupt Enable Set Register 0
  fields as sec_enable_set_reg0
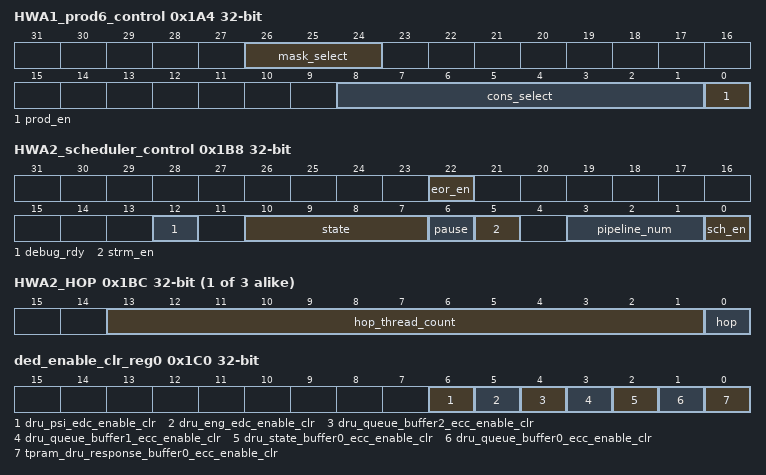
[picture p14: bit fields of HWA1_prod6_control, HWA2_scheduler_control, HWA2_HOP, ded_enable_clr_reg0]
0x1A4 HWA1_prod6_control — Controlling producer socket6 for HWA1
  [26:24] mask_select — define which tdone_mask apply to prod socket 6. tdone_mask[mask_select] applies to prod_socket6
  [8:1] cons_select — consumer select for HWA1 prod socket 6. Used in decrementing count of producer buffer
  [0] prod_en — '1' -> Producer socket 0 enable , '0' Disable
0x1B8 HWA2_scheduler_control access per field — Scheduler Control Register
  [22] eor_en rw — '1' -> LDC REGION/sub-frame feature enabled, '0' LDC works in Frame mode only
  [12] debug_rdy rw — '0' -> HWA2 Scheduler resources must not be read during halted state. '1'-> HWA2 Scheduler resources are readable during halted state
  [10:7] state ro — Current state of HWA2 Scheduler
  [6] pause rw — '1' -> pause/suspend scheduler , '0' -> resume scheduler
  [5] strm_en rw — '1' -> Streaming input enable, '0' No streaming input
  [3:1] pipeline_num rw — Pipeline Number of HWA2 Scheduler
  [0] sch_en rw — scheduler enable; write '1' to enable scheduler
{0x44+0xBC*i} HWA{i}_HOP (i=2..4) — Scheduler HOP Control Register. Help in detecting eop within scheduler. Once configured, it counts task/channel starts and stops issuing further starts. Specifically useful for Head of pipe dma scheduler .
  fields as HWA0_HOP
0x1C0 ded_enable_clr_reg0 — Interrupt Enable Clear Register 0
  fields as sec_enable_clr_reg0
{0x1C8+4i} HWA2_cons{i}_control (i=0..2) — Controlling consumer socket {i} for HWA2
  [9:1] prod_select — producer select for HWA2 cons socket {i}
  [0] cons_en — '1' -> Consumer socket {i} enable , '0' Disable
{0x1D4+0x14*i} HWA2_prod{i}_control (i=0..3) — Controlling producer socket{i} for HWA2
  [23:22] partial_bpr_trigmode — 0: Normal behavior; 1 : Prod Socket {i} is used to trigger DMA channel to transfer end of Row or End of Region Row buffer data for prod socket ({i}+2)%4. Useful when this Buffer is not completely filled at end of row and it enables triggering separate DMA channel for end of row. Rely on tdone_bpr_early attribute; 2: Prod Socket {i} is used to trigger DMA channel to transfer end of Row or End of Region Row buffer data for prod socket ({i}+2)%4. Useful when this Buffer is not completely filled at end of row and it enables triggering separate DMA channel for end of row. Rely on end of Row attribute. Must not be used in dual output mode
  [21:18] partial_bpr_count — Remaining block count to complete configured BPR at End of Row or End of Region Row when LDC is configured in tdone_gen_mode='0'
  [8:1] cons_select — consumer select for HWA2 prod socket {i}. Used in decrementing count of producer buffer
  [0] prod_en — '1' -> Producer socket 0 enable , '0' Disable
{0x1D8+0x14*i} HWA2_prod{i}_buf_control (i=0..7) — Controlling producer socket{i} buffer for HWA2
  fields as HWA0_prod0_buf_control
{0x1DC+0x14*i} HWA2_prod{i}_count access per field (i=0..7) — Defining count values for pre/post load for generating pend by HWA2 prod{i}
  fields as HWA0_prod0_count
{0x1E0+0x14*i} HWA2_pa{i}_control (i=0..6) — control register to manage pattern adapter on HWA2 prod socket{i}
  fields as HWA0_pa0_control
0x1E0 dbg ro — The DBG register returns the current status of internal FSM - TI internal use only.
  [32:0] status — Debug status
0x1E0 dbg ro — The DBG register returns the current status of internal FSM - TI internal use only.
  [32:0] status — Debug status
{0x1E4+0x14*i} HWA2_pa{i}_prodcount access per field (i=0..6) — count values for HWA2 prod socket{i}
  fields as HWA0_pa0_prodcount
0x200 aggr_enable_set — AGGR interrupt enable set Register
  [1] timeout — interrupt enable set for svbus timeout errors
  [0] parity — interrupt enable set for parity errors
0x204 aggr_enable_clr — AGGR interrupt enable clear Register
  [1] timeout — interrupt enable clear for svbus timeout errors
  [0] parity — interrupt enable clear for parity errors
0x208 aggr_status_set — AGGR interrupt status set Register
  [3:2] timeout — interrupt status set for svbus timeout errors
  [1:0] parity — interrupt status set for parity errors
0x20C aggr_status_clr — AGGR interrupt status clear Register
  [3:2] timeout — interrupt status clear for svbus timeout errors
  [1:0] parity — interrupt status clear for parity errors
{0x1D4+0x14*i} HWA2_prod{i}_control (i=4..7) — Controlling producer socket{i} for HWA2
  [25:24] mask_select — define which tdone_mask apply to prod socket {i}. tdone_mask[mask_select] applies to prod_socket{i}.
  [8:1] cons_select — consumer select for HWA2 prod socket {i}. Used in decrementing count of producer buffer
  [0] prod_en — '1' -> Producer socket 0 enable , '0' Disable
0x274 HWA3_scheduler_control access per field — Scheduler Control Register
  [22] eor_en rw — '1' -> LDC REGION/sub-frame feature enabled, '0' LDC works in Frame mode only
  [12] debug_rdy rw — '0' -> HWA3 Scheduler resources must not be read during halted state. '1'-> HWA3 Scheduler resources are readable during halted state
  [10:7] state ro — Current state of HWA3 Scheduler
  [6] pause rw — '1' -> pause/suspend scheduler , '0' -> resume scheduler
  [5] strm_en rw — '1' -> Streaming input enable, '0' No streaming input
  [3:1] pipeline_num rw — Pipeline Number of HWA3 Scheduler
  [0] sch_en rw — scheduler enable; write '1' to enable scheduler
0x27C HWA3_WDTimer access per field — Watchdog timer control register
  [24:8] wdtimer_count ro — Current value of HWA3 Scheduler watchdog timer count
  [2] wdtimer_mode rw — Watchdog timeout count '1' -> 128K , '0' -> 64K
  [1] wdtimer_status ro — HWA3 Scheduler watchdog timer status '1' -> Timer Active '0' -> Timer Inactive (count is stable)
  [0] wdtimer_en rw — '1' -> activate watchdog timer for 64K VPAC/DMPAC cycles between task start and task done '0' -> Disable watchdog timer
0x280 HWA3_BW_limiter — Scheduler BW Control Register. Processing unit level BW control. Use DMA to eliminate peak system BW within processing units line/Block
  [22:8] BW_cycle_count — Average Cycle count between successive Task Start
  [4:1] BW_token_count — Max Token count to create average BW
  [0] BW_limiter_en — '1' -> Enable BW limiter function for HWA3 sch, '0' --> Disable
{0x284+4i} HWA3_cons{i}_control (i=0..2) — Controlling consumer socket {i} for HWA3
  [9:1] prod_select — producer select for HWA3 cons socket {i}
  [0] cons_en — '1' -> Consumer socket {i} enable , '0' Disable
{0x290+0x14*i} HWA3_prod{i}_control (i=0..3) — Controlling producer socket{i} for HWA3
  [23:22] partial_bpr_trigmode — 0: Normal behavior; 1 : Prod Socket {i} is used to trigger DMA channel to transfer end of Row or End of Region Row buffer data for prod socket ({i}+2)%4. Useful when this Buffer is not completely filled at end of row and it enables triggering separate DMA channel for end of row. Rely on tdone_bpr_early attribute; 2: Prod Socket {i} is used to trigger DMA channel to transfer end of Row or End of Region Row buffer data for prod socket ({i}+2)%4. Useful when this Buffer is not completely filled at end of row and it enables triggering separate DMA channel for end of row. Rely on end of Row attribute. Must not be used in dual output mode
  [21:18] partial_bpr_count — Remaining block count to complete configured BPR at End of Row or End of Region Row when LDC is configured in tdone_gen_mode='0'
  [8:1] cons_select — consumer select for HWA3 prod socket {i}. Used in decrementing count of producer buffer
  [0] prod_en — '1' -> Producer socket 0 enable , '0' Disable
{0x294+0x14*i} HWA3_prod{i}_buf_control (i=0..7) — Controlling producer socket{i} buffer for HWA3
  fields as HWA0_prod0_buf_control
{0x298+0x14*i} HWA3_prod{i}_count access per field (i=0..7) — Defining count values for pre/post load for generating pend by HWA3 prod{i}
  fields as HWA0_prod0_count
{0x29C+0x14*i} HWA3_pa{i}_control (i=0..6) — control register to manage pattern adapter on HWA3 prod socket{i}
  fields as HWA0_pa0_control
{0x2A0+0x14*i} HWA3_pa{i}_prodcount access per field (i=0..6) — count values for HWA3 prod socket{i}
  fields as HWA0_pa0_prodcount
{0x290+0x14*i} HWA3_prod{i}_control (i=4..7) — Controlling producer socket{i} for HWA3
  [25:24] mask_select — define which tdone_mask apply to prod socket {i}. tdone_mask[mask_select] applies to prod_socket{i}.
  [8:1] cons_select — consumer select for HWA3 prod socket {i}. Used in decrementing count of producer buffer
  [0] prod_en — '1' -> Producer socket 0 enable , '0' Disable
0x300 enable_clr_reg_level_dmpac_out_0_0 — Enable Clear Register 0
  [25] enable_level_dmpac_out_0_en_foco_1_sl2_wr_err_clr — Enable Clear for level_dmpac_out_0_en_foco_1_sl2_wr_err
  [24] enable_level_dmpac_out_0_en_foco_1_sl2_rd_err_clr — Enable Clear for level_dmpac_out_0_en_foco_1_sl2_rd_err
  [23] enable_level_dmpac_out_0_en_foco_1_fr_done_evt_clr — Enable Clear for level_dmpac_out_0_en_foco_1_fr_done_evt
  [22] enable_level_dmpac_out_0_en_foco_0_sl2_wr_err_clr — Enable Clear for level_dmpac_out_0_en_foco_0_sl2_wr_err
  [21] enable_level_dmpac_out_0_en_foco_0_sl2_rd_err_clr — Enable Clear for level_dmpac_out_0_en_foco_0_sl2_rd_err
  [20] enable_level_dmpac_out_0_en_foco_0_fr_done_evt_clr — Enable Clear for level_dmpac_out_0_en_foco_0_fr_done_evt
  [19] enable_level_dmpac_out_0_en_sde_write_error_clr — Enable Clear for level_dmpac_out_0_en_sde_write_error
  [18] enable_level_dmpac_out_0_en_sde_read_error_clr — Enable Clear for level_dmpac_out_0_en_sde_read_error
  [17] enable_level_dmpac_out_0_en_sde_frame_done_clr — Enable Clear for level_dmpac_out_0_en_sde_frame_done
  [16] enable_level_dmpac_out_0_en_sde_blk_done_clr — Enable Clear for level_dmpac_out_0_en_sde_blk_done
  [4] enable_level_dmpac_out_0_en_dof_mp0_rd_status_error_clr — Enable Clear for level_dmpac_out_0_en_dof_mp0_rd_status_error
  [3] enable_level_dmpac_out_0_en_dof_write_error_clr — Enable Clear for level_dmpac_out_0_en_dof_write_error
  [2] enable_level_dmpac_out_0_en_dof_read_error_clr — Enable Clear for level_dmpac_out_0_en_dof_read_error
  [1] enable_level_dmpac_out_0_en_dof_frame_done_clr — Enable Clear for level_dmpac_out_0_en_dof_frame_done
  [0] enable_level_dmpac_out_0_en_dof_row_done_clr — Enable Clear for level_dmpac_out_0_en_dof_row_done
0x300 dofcshist ro — Confidence Score Histogram Number of pixels having confidence score value of Bin Index
  [24:0] bin_sts — Number of pixels having confidence score value of Bin Index
0x304 enable_clr_reg_level_dmpac_out_0_1 — Enable Clear Register 1
  [27] enable_level_dmpac_out_0_en_tdone_8_clr — Enable Clear for level_dmpac_out_0_en_tdone_8
  [26] enable_level_dmpac_out_0_en_tdone_7_clr — Enable Clear for level_dmpac_out_0_en_tdone_7
  [25] enable_level_dmpac_out_0_en_tdone_1_clr — Enable Clear for level_dmpac_out_0_en_tdone_1
  [24] enable_level_dmpac_out_0_en_tdone_0_clr — Enable Clear for level_dmpac_out_0_en_tdone_0
  [19] enable_level_dmpac_out_0_en_spare_pend_1_l_clr — Enable Clear for level_dmpac_out_0_en_spare_pend_1_l
  [18] enable_level_dmpac_out_0_en_spare_pend_1_p_clr — Enable Clear for level_dmpac_out_0_en_spare_pend_1_p
  [17] enable_level_dmpac_out_0_en_spare_pend_0_l_clr — Enable Clear for level_dmpac_out_0_en_spare_pend_0_l
  [16] enable_level_dmpac_out_0_en_spare_pend_0_p_clr — Enable Clear for level_dmpac_out_0_en_spare_pend_0_p
  [9] enable_level_dmpac_out_0_en_spare_dec_1_clr — Enable Clear for level_dmpac_out_0_en_spare_dec_1
  [8] enable_level_dmpac_out_0_en_spare_dec_0_clr — Enable Clear for level_dmpac_out_0_en_spare_dec_0
  [n] enable_level_dmpac_out_0_en_pipe_done_{n}_clr (n=0..3) — Enable Clear for level_dmpac_out_0_en_pipe_done_{n}
